AUTOSAR XML (schema 4-3-0)
package /ComponentTypes
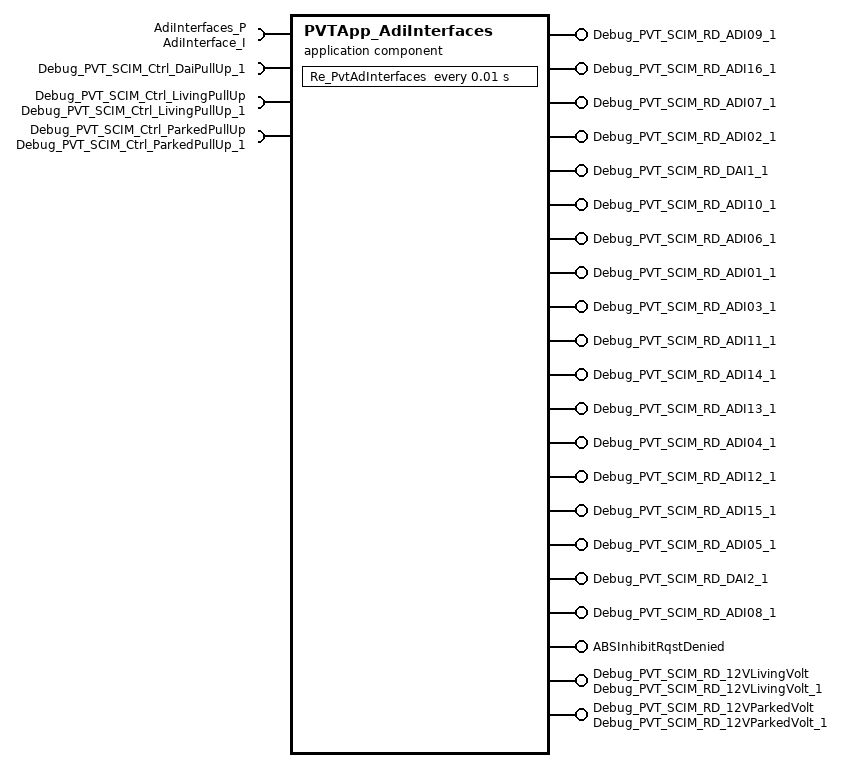
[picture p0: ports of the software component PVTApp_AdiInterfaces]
  application sw component type PVTApp_AdiInterfaces
    require port AdiInterfaces_P: required-com-specs=[SetPullUp, GetPullUpState, GetAdiPinStateAll, GetAdiPinState], required-interface=AdiInterface_I
    require port Debug_PVT_SCIM_Ctrl_DaiPullUp_1: nonqueued-receiver-com-spec{data-element=Debug_PVT_SCIM_Ctrl_DaiPullUp, init-value=0}, required-interface=Debug_PVT_SCIM_Ctrl_DaiPullUp_1
    18 x provide port:
      Debug_PVT_SCIM_RD_ADI09_1: nonqueued-sender-com-spec{data-element=Debug_PVT_SCIM_RD_ADI09, init-value=0}, provided-interface=Debug_PVT_SCIM_RD_ADI09_1
      Debug_PVT_SCIM_RD_ADI16_1: nonqueued-sender-com-spec{data-element=Debug_PVT_SCIM_RD_ADI16, init-value=0}, provided-interface=Debug_PVT_SCIM_RD_ADI16_1
      Debug_PVT_SCIM_RD_ADI07_1: nonqueued-sender-com-spec{data-element=Debug_PVT_SCIM_RD_ADI07, init-value=0}, provided-interface=Debug_PVT_SCIM_RD_ADI07_1
      Debug_PVT_SCIM_RD_ADI02_1: nonqueued-sender-com-spec{data-element=Debug_PVT_SCIM_RD_ADI02, init-value=0}, provided-interface=Debug_PVT_SCIM_RD_ADI02_1
      Debug_PVT_SCIM_RD_DAI1_1: nonqueued-sender-com-spec{data-element=Debug_PVT_SCIM_RD_DAI1, init-value=0}, provided-interface=Debug_PVT_SCIM_RD_DAI1_1
      Debug_PVT_SCIM_RD_ADI10_1: nonqueued-sender-com-spec{data-element=Debug_PVT_SCIM_RD_ADI10, init-value=0}, provided-interface=Debug_PVT_SCIM_RD_ADI10_1
      Debug_PVT_SCIM_RD_ADI06_1: nonqueued-sender-com-spec{data-element=Debug_PVT_SCIM_RD_ADI06, init-value=0}, provided-interface=Debug_PVT_SCIM_RD_ADI06_1
      Debug_PVT_SCIM_RD_ADI01_1: nonqueued-sender-com-spec{data-element=Debug_PVT_SCIM_RD_ADI01, init-value=0}, provided-interface=Debug_PVT_SCIM_RD_ADI01_1
      Debug_PVT_SCIM_RD_ADI03_1: nonqueued-sender-com-spec{data-element=Debug_PVT_SCIM_RD_ADI03, init-value=0}, provided-interface=Debug_PVT_SCIM_RD_ADI03_1
      Debug_PVT_SCIM_RD_ADI11_1: nonqueued-sender-com-spec{data-element=Debug_PVT_SCIM_RD_ADI11, init-value=0}, provided-interface=Debug_PVT_SCIM_RD_ADI11_1
      Debug_PVT_SCIM_RD_ADI14_1: nonqueued-sender-com-spec{data-element=Debug_PVT_SCIM_RD_ADI14, init-value=0}, provided-interface=Debug_PVT_SCIM_RD_ADI14_1
      Debug_PVT_SCIM_RD_ADI13_1: nonqueued-sender-com-spec{data-element=Debug_PVT_SCIM_RD_ADI13, init-value=0}, provided-interface=Debug_PVT_SCIM_RD_ADI13_1
      Debug_PVT_SCIM_RD_ADI04_1: nonqueued-sender-com-spec{data-element=Debug_PVT_SCIM_RD_ADI04, init-value=0}, provided-interface=Debug_PVT_SCIM_RD_ADI04_1
      Debug_PVT_SCIM_RD_ADI12_1: nonqueued-sender-com-spec{data-element=Debug_PVT_SCIM_RD_ADI12, init-value=0}, provided-interface=Debug_PVT_SCIM_RD_ADI12_1
      Debug_PVT_SCIM_RD_ADI15_1: nonqueued-sender-com-spec{data-element=Debug_PVT_SCIM_RD_ADI15, init-value=0}, provided-interface=Debug_PVT_SCIM_RD_ADI15_1
      Debug_PVT_SCIM_RD_ADI05_1: nonqueued-sender-com-spec{data-element=Debug_PVT_SCIM_RD_ADI05, init-value=0}, provided-interface=Debug_PVT_SCIM_RD_ADI05_1
      Debug_PVT_SCIM_RD_DAI2_1: nonqueued-sender-com-spec{data-element=Debug_PVT_SCIM_RD_DAI2, init-value=0}, provided-interface=Debug_PVT_SCIM_RD_DAI2_1
      Debug_PVT_SCIM_RD_ADI08_1: nonqueued-sender-com-spec{data-element=Debug_PVT_SCIM_RD_ADI08, init-value=0}, provided-interface=Debug_PVT_SCIM_RD_ADI08_1
    require port Debug_PVT_SCIM_Ctrl_LivingPullUp: nonqueued-receiver-com-spec{data-element=Debug_PVT_SCIM_Ctrl_LivingPullUp, init-value=0}, required-interface=Debug_PVT_SCIM_Ctrl_LivingPullUp_1
    require port Debug_PVT_SCIM_Ctrl_ParkedPullUp: nonqueued-receiver-com-spec{data-element=Debug_PVT_SCIM_Ctrl_ParkedPullUp, init-value=0}, required-interface=Debug_PVT_SCIM_Ctrl_ParkedPullUp_1
    provide port ABSInhibitRqstDenied: nonqueued-sender-com-spec{data-element=ABSInhibitRqstDenied, init-value=3}, provided-interface=ABSInhibitRqstDenied
    provide port Debug_PVT_SCIM_RD_12VLivingVolt: nonqueued-sender-com-spec{data-element=Debug_PVT_SCIM_RD_12VLivingVolt, init-value=0}, provided-interface=Debug_PVT_SCIM_RD_12VLivingVolt_1
    provide port Debug_PVT_SCIM_RD_12VParkedVolt: nonqueued-sender-com-spec{data-element=Debug_PVT_SCIM_RD_12VParkedVolt, init-value=0}, provided-interface=Debug_PVT_SCIM_RD_12VParkedVolt_1
    behavior PVTApp_AdiInterfaces_InternalBehavior
      timing event TMT_Re_PvtAdInterfaces: start-on-event=Re_PvtAdInterfaces, period=0.01
      runnable Re_PvtAdInterfaces
        data-receive-point-by-values:
          access REC_Debug_PVT_SCIM_Ctrl_DaiPullUp_1_Debug_PVT_SCIM_Ctrl_DaiPullUp: accessed-variable=Debug_PVT_SCIM_Ctrl_DaiPullUp_1.Debug_PVT_SCIM_Ctrl_DaiPullUp
          access REC_Debug_PVT_SCIM_Ctrl_LivingPullUp_Debug_PVT_SCIM_Ctrl_LivingPullUp: accessed-variable=Debug_PVT_SCIM_Ctrl_LivingPullUp.Debug_PVT_SCIM_Ctrl_LivingPullUp
          access REC_Debug_PVT_SCIM_Ctrl_ParkedPullUp_Debug_PVT_SCIM_Ctrl_ParkedPullUp: accessed-variable=Debug_PVT_SCIM_Ctrl_ParkedPullUp.Debug_PVT_SCIM_Ctrl_ParkedPullUp
        data-send-points:
          20 x access:
            SEND_Debug_PVT_SCIM_RD_ADI{01..16}_1_Debug_PVT_SCIM_RD_ADI{01..16}: accessed-variable=Debug_PVT_SCIM_RD_ADI{01..16}_1.Debug_PVT_SCIM_RD_ADI{01..16}
            SEND_Debug_PVT_SCIM_RD_DAI1_1_Debug_PVT_SCIM_RD_DAI1: accessed-variable=Debug_PVT_SCIM_RD_DAI1_1.Debug_PVT_SCIM_RD_DAI1
            SEND_Debug_PVT_SCIM_RD_DAI2_1_Debug_PVT_SCIM_RD_DAI2: accessed-variable=Debug_PVT_SCIM_RD_DAI2_1.Debug_PVT_SCIM_RD_DAI2
            SEND_Debug_PVT_SCIM_RD_12VLivingVolt_Debug_PVT_SCIM_RD_12VLivingVolt: accessed-variable=Debug_PVT_SCIM_RD_12VLivingVolt.Debug_PVT_SCIM_RD_12VLivingVolt
            SEND_Debug_PVT_SCIM_RD_12VParkedVolt_Debug_PVT_SCIM_RD_12VParkedVolt: accessed-variable=Debug_PVT_SCIM_RD_12VParkedVolt.Debug_PVT_SCIM_RD_12VParkedVolt
        4 x sync call:
          SC_AdiInterfaces_P_GetAdiPinState: operation=AdiInterfaces_P.GetAdiPinState
          SC_AdiInterfaces_P_GetAdiPinStateAll: operation=AdiInterfaces_P.GetAdiPinStateAll
          SC_AdiInterfaces_P_GetPullUpState: operation=AdiInterfaces_P.GetPullUpState
          SC_AdiInterfaces_P_SetPullUp: operation=AdiInterfaces_P.SetPullUp
  swc implementation PVTApp_AdiInterfaces_Implementation: behavior=PVTApp_AdiInterfaces_InternalBehavior
    code-descriptors:
      code Default: artifact-descriptors=autosar-engineering-object=category=SWSRC
